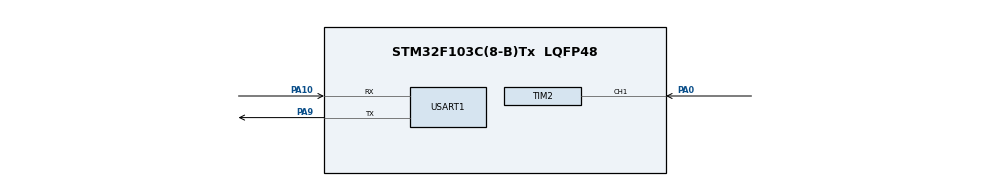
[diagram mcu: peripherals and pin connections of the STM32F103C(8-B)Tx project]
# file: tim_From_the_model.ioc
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Mcu.Family=STM32F1
Mcu.Name=STM32F103C(8-B)Tx
Mcu.Package=LQFP48
NVIC.PriorityGroup=NVIC_PRIORITYGROUP_4
NVIC.TIM2_IRQn=true\:0\:0\:false\:false\:true\:true\:true\:true
PA0-WKUP.Signal=S_TIM2_CH1_ETR
PA10.Mode=Asynchronous
PA10.Signal=USART1_RX
PA13.Mode=Serial_Wire
PA13.Signal=SYS_JTMS-SWDIO
PA14.Mode=Serial_Wire
PA14.Signal=SYS_JTCK-SWCLK
PA9.Mode=Asynchronous
PA9.Signal=USART1_TX
ProjectManager.HeapSize=0x200
ProjectManager.StackSize=0x400
ProjectManager.TargetToolchain=CMake
RCC.APB1Freq_Value=8000000
RCC.APB2Freq_Value=8000000
SH.S_TIM2_CH1_ETR.0=TIM2_CH1,TriggerSource_TI1FP1
TIM2.Period=4999
TIM2.Prescaler=7999
USART1.VirtualMode=VM_ASYNC
VP_TIM2_VS_ClockSourceINT.Mode=Internal
VP_TIM2_VS_ControllerModeReset.Mode=Reset Mode
board=custom

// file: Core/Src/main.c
/* USER CODE BEGIN Header */
/**
  ******************************************************************************
  * @file           : main.c
  * @brief          : Main program body
  ******************************************************************************
  * @attention
  *
  * Copyright (c) 2026 STMicroelectronics.
  * All rights reserved.
  *
  * This software is licensed under terms that can be found in the LICENSE file
  * in the root directory of this software component.
  * If no LICENSE file comes with this software, it is provided AS-IS.
  *
  ******************************************************************************
  */
/* USER CODE END Header */
#include "main.h"

/* USER CODE BEGIN Includes */
#include "stm32f1xx.h"
#include "stm32f1xx_hal_tim.h"
#include "string.h"
#include "stdio.h"
#include <stdint.h>
#include <sys/_intsup.h>
/* USER CODE END Includes */

TIM_HandleTypeDef htim2;

UART_HandleTypeDef huart1;

/* USER CODE BEGIN PV */
volatile uint8_t TIM_FLAG = 0;
char updatemsg[] = "Auto Reload\r\n";
char triggermsg[] = "External trigger\r\n";
/* USER CODE END PV */

void SystemClock_Config(void);
static void MX_GPIO_Init(void);
static void MX_TIM2_Init(void);
static void MX_USART1_UART_Init(void);

/* USER CODE BEGIN 0 */
void HAL_TIM_PeriodElapsedCallback(TIM_HandleTypeDef *htim)
{
  if(htim == &htim2)
  {
    TIM_FLAG = 1;
  }
}
/* USER CODE END 0 */

int main(void)
{

  /* MCU Configuration--------------------------------------------------------*/

  /* Reset of all peripherals, Initializes the Flash interface and the Systick. */
  HAL_Init();

  /* Configure the system clock */
  SystemClock_Config();

  /* Initialize all configured peripherals */
  MX_GPIO_Init();
  MX_TIM2_Init();
  MX_USART1_UART_Init();
  /* USER CODE BEGIN 2 */
HAL_TIM_Base_Start_IT(&htim2);
int counter = 0;
char message[20] = "";
  /* USER CODE END 2 */

  /* Infinite loop */
  /* USER CODE BEGIN WHILE */
  while (1)
  {
    counter = __HAL_TIM_GET_COUNTER(&htim2);
    sprintf(message,"counter:%d\r\n",counter);
    HAL_UART_Transmit(&huart1,(uint8_t *)message,strlen(message),100);

    if(TIM_FLAG == 1)
    {
      TIM_FLAG = 0;
      if(__HAL_TIM_GET_FLAG(&htim2,TIM_FLAG_TRIGGER) != RESET)
      {
        __HAL_TIM_CLEAR_FLAG(&htim2,TIM_FLAG_TRIGGER);
        HAL_UART_Transmit(&huart1,(uint8_t *)triggermsg,strlen(triggermsg),100);
      }
      else
      {
        HAL_UART_Transmit(&huart1,(uint8_t *)updatemsg,strlen(updatemsg),100);
      }
    }
    HAL_Delay(500);
    /* USER CODE END WHILE */

  }
}

void SystemClock_Config(void)
{
  RCC_OscInitTypeDef RCC_OscInitStruct = {0};
  RCC_ClkInitTypeDef RCC_ClkInitStruct = {0};

  /** Initializes the RCC Oscillators according to the specified parameters
  * in the RCC_OscInitTypeDef structure.
  */
  RCC_OscInitStruct.OscillatorType = RCC_OSCILLATORTYPE_HSI;
  RCC_OscInitStruct.HSIState = RCC_HSI_ON;
  RCC_OscInitStruct.HSICalibrationValue = RCC_HSICALIBRATION_DEFAULT;
  RCC_OscInitStruct.PLL.PLLState = RCC_PLL_NONE;
  if (HAL_RCC_OscConfig(&RCC_OscInitStruct) != HAL_OK)
  {
    Error_Handler();
  }

  /** Initializes the CPU, AHB and APB buses clocks
  */
  RCC_ClkInitStruct.ClockType = RCC_CLOCKTYPE_HCLK|RCC_CLOCKTYPE_SYSCLK
                              |RCC_CLOCKTYPE_PCLK1|RCC_CLOCKTYPE_PCLK2;
  RCC_ClkInitStruct.SYSCLKSource = RCC_SYSCLKSOURCE_HSI;
  RCC_ClkInitStruct.AHBCLKDivider = RCC_SYSCLK_DIV1;
  RCC_ClkInitStruct.APB1CLKDivider = RCC_HCLK_DIV1;
  RCC_ClkInitStruct.APB2CLKDivider = RCC_HCLK_DIV1;

  if (HAL_RCC_ClockConfig(&RCC_ClkInitStruct, FLASH_LATENCY_0) != HAL_OK)
  {
    Error_Handler();
  }
}

static void MX_TIM2_Init(void)
{

  TIM_ClockConfigTypeDef sClockSourceConfig = {0};
  TIM_SlaveConfigTypeDef sSlaveConfig = {0};
  TIM_MasterConfigTypeDef sMasterConfig = {0};

  htim2.Instance = TIM2;
  htim2.Init.Prescaler = 7999;
  htim2.Init.CounterMode = TIM_COUNTERMODE_UP;
  htim2.Init.Period = 4999;
  htim2.Init.ClockDivision = TIM_CLOCKDIVISION_DIV1;
  htim2.Init.AutoReloadPreload = TIM_AUTORELOAD_PRELOAD_DISABLE;
  if (HAL_TIM_Base_Init(&htim2) != HAL_OK)
  {
    Error_Handler();
  }
  sClockSourceConfig.ClockSource = TIM_CLOCKSOURCE_INTERNAL;
  if (HAL_TIM_ConfigClockSource(&htim2, &sClockSourceConfig) != HAL_OK)
  {
    Error_Handler();
  }
  sSlaveConfig.SlaveMode = TIM_SLAVEMODE_RESET;
  sSlaveConfig.InputTrigger = TIM_TS_TI1FP1;
  sSlaveConfig.TriggerPolarity = TIM_TRIGGERPOLARITY_RISING;
  sSlaveConfig.TriggerFilter = 0;
  if (HAL_TIM_SlaveConfigSynchro(&htim2, &sSlaveConfig) != HAL_OK)
  {
    Error_Handler();
  }
  sMasterConfig.MasterOutputTrigger = TIM_TRGO_RESET;
  sMasterConfig.MasterSlaveMode = TIM_MASTERSLAVEMODE_DISABLE;
  if (HAL_TIMEx_MasterConfigSynchronization(&htim2, &sMasterConfig) != HAL_OK)
  {
    Error_Handler();
  }

}

static void MX_USART1_UART_Init(void)
{

  huart1.Instance = USART1;
  huart1.Init.BaudRate = 115200;
  huart1.Init.WordLength = UART_WORDLENGTH_8B;
  huart1.Init.StopBits = UART_STOPBITS_1;
  huart1.Init.Parity = UART_PARITY_NONE;
  huart1.Init.Mode = UART_MODE_TX_RX;
  huart1.Init.HwFlowCtl = UART_HWCONTROL_NONE;
  huart1.Init.OverSampling = UART_OVERSAMPLING_16;
  if (HAL_UART_Init(&huart1) != HAL_OK)
  {
    Error_Handler();
  }

}

static void MX_GPIO_Init(void)
{

  /* GPIO Ports Clock Enable */
  __HAL_RCC_GPIOA_CLK_ENABLE();

}

void Error_Handler(void)
{
  __disable_irq();
  while (1)
  {
  }
}
